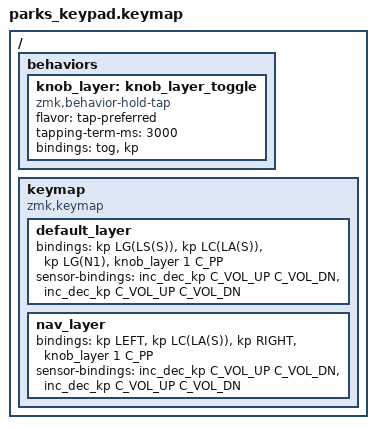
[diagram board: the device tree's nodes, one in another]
#include <behaviors.dtsi>
#include <dt-bindings/zmk/keys.h>

/ {
    behaviors {
        knob_layer: knob_layer_toggle {
            compatible = "zmk,behavior-hold-tap";
            #binding-cells = <2>;
            flavor = "tap-preferred";
            tapping-term-ms = <3000>;
            bindings = <&tog>, <&kp>;
        };
    };

    keymap {
        compatible = "zmk,keymap";

        // Layer 0: 기본 매핑
        default_layer {
            bindings = <
                &kp LG(LS(S))    &kp LC(LA(S))    &kp LG(N1)    &knob_layer 1 C_PP
            >;
            // 0번 슬롯과 1번 슬롯 모두에 볼륨 업/다운을 할당
            sensor-bindings = <&inc_dec_kp C_VOL_UP C_VOL_DN &inc_dec_kp C_VOL_UP C_VOL_DN>;
        };

        // Layer 1: 방향키 매핑
        nav_layer {
            bindings = <
                &kp LEFT         &kp LC(LA(S))    &kp RIGHT     &knob_layer 1 C_PP
            >;
            // 0번 슬롯과 1번 슬롯 모두에 볼륨 업/다운을 할당
            sensor-bindings = <&inc_dec_kp C_VOL_UP C_VOL_DN &inc_dec_kp C_VOL_UP C_VOL_DN>;
        };
    };
};
